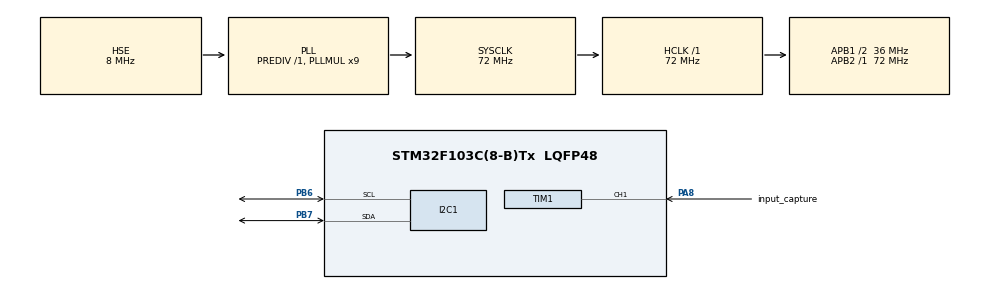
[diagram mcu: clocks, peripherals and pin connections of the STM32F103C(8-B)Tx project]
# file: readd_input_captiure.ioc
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Mcu.Family=STM32F1
Mcu.Name=STM32F103C(8-B)Tx
Mcu.Package=LQFP48
NVIC.PriorityGroup=NVIC_PRIORITYGROUP_4
NVIC.TIM1_CC_IRQn=true\:0\:0\:false\:false\:true\:true\:true\:true
PA13.Mode=Serial_Wire
PA13.Signal=SYS_JTMS-SWDIO
PA14.Mode=Serial_Wire
PA14.Signal=SYS_JTCK-SWCLK
PA8.GPIO_Label=input_capture
PA8.Signal=S_TIM1_CH1
PB6.Mode=I2C
PB6.Signal=I2C1_SCL
PB7.Mode=I2C
PB7.Signal=I2C1_SDA
PD0-OSC_IN.Mode=HSE-External-Oscillator
PD0-OSC_IN.Signal=RCC_OSC_IN
PD1-OSC_OUT.Mode=HSE-External-Oscillator
PD1-OSC_OUT.Signal=RCC_OSC_OUT
ProjectManager.HeapSize=0x200
ProjectManager.StackSize=0x400
ProjectManager.TargetToolchain=STM32CubeIDE
RCC.AHBFreq_Value=72000000
RCC.APB1CLKDivider=RCC_HCLK_DIV2
RCC.APB1Freq_Value=36000000
RCC.APB1TimFreq_Value=72000000
RCC.APB2Freq_Value=72000000
RCC.APB2TimFreq_Value=72000000
RCC.HCLKFreq_Value=72000000
RCC.PLLMUL=RCC_PLL_MUL9
RCC.PLLSourceVirtual=RCC_PLLSOURCE_HSE
RCC.SYSCLKFreq_VALUE=72000000
RCC.SYSCLKSource=RCC_SYSCLKSOURCE_PLLCLK
RCC.USBFreq_Value=72000000
SH.S_TIM1_CH1.0=TIM1_CH1,Input_Capture1_from_TI1
TIM1.Channel-Input_Capture1_from_TI1=TIM_CHANNEL_1
TIM1.Prescaler=71
board=custom

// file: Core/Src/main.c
#include "main.h"
#include<stdio.h>

I2C_HandleTypeDef hi2c1;

TIM_HandleTypeDef htim1;

void SystemClock_Config(void);
static void MX_GPIO_Init(void);
static void MX_I2C1_Init(void);
static void MX_TIM1_Init(void);

char lcd_buffer[16];
uint32_t IC_Value1 = 0, IC_Value2 = 0, Difference = 0;

uint8_t Is_First_Captured = 0;
float Distance = 0;

/* USER CODE BEGIN PFP */
void HAL_TIM_IC_CaptureCallback(TIM_HandleTypeDef *htim) {
    if (htim->Instance == TIM1 && htim->Channel == HAL_TIM_ACTIVE_CHANNEL_1) {
        if (Is_First_Captured == 0) { // Nếu đây là cạnh lên đầu tiên
            start = HAL_TIM_ReadCapturedValue(htim, TIM_CHANNEL_1);  // Lưu thời điểm bắt đầu xung
            Is_First_Captured = 1;  // Đánh dấu đã bắt đầu đo
            __HAL_TIM_SET_COUNTER(&htim1, 0);  // Reset bộ đếm Timer 1
        } else { // Nếu đây là cạnh xuống
            stop = HAL_TIM_ReadCapturedValue(htim, TIM_CHANNEL_1);  // Lưu thời điểm kết thúc xung

            // Xử lý tính toán khoảng cách
            if (stop > start) {
                Difference = stop - start;
            } else { // Nếu bộ đếm bị tràn (overflow)
                Difference = (0xFFFF - start) + stop;
            }

            distance = Difference * 0.0343 / 2;  // Tính khoảng cách (cm)
            Is_First_Captured = 0;  // Reset trạng thái đo
        }
    }
}

/* USER CODE END PFP */

int main(void)
{

  /* MCU Configuration--------------------------------------------------------*/

  /* Reset of all peripherals, Initializes the Flash interface and the Systick. */
  HAL_Init();

  /* Configure the system clock */
  SystemClock_Config();

  /* Initialize all configured peripherals */
  MX_GPIO_Init();
  MX_I2C1_Init();
  MX_TIM1_Init();
  /* USER CODE BEGIN 2 */
HAL_TIM_Base_Start_IT(&htim1);
  /* USER CODE END 2 */

  /* Infinite loop */
  while (1)
  {

  }
}

void SystemClock_Config(void)
{
  RCC_OscInitTypeDef RCC_OscInitStruct = {0};
  RCC_ClkInitTypeDef RCC_ClkInitStruct = {0};

  /** Initializes the RCC Oscillators according to the specified parameters
  * in the RCC_OscInitTypeDef structure.
  */
  RCC_OscInitStruct.OscillatorType = RCC_OSCILLATORTYPE_HSE;
  RCC_OscInitStruct.HSEState = RCC_HSE_ON;
  RCC_OscInitStruct.HSEPredivValue = RCC_HSE_PREDIV_DIV1;
  RCC_OscInitStruct.HSIState = RCC_HSI_ON;
  RCC_OscInitStruct.PLL.PLLState = RCC_PLL_ON;
  RCC_OscInitStruct.PLL.PLLSource = RCC_PLLSOURCE_HSE;
  RCC_OscInitStruct.PLL.PLLMUL = RCC_PLL_MUL9;
  if (HAL_RCC_OscConfig(&RCC_OscInitStruct) != HAL_OK)
  {
    Error_Handler();
  }

  /** Initializes the CPU, AHB and APB buses clocks
  */
  RCC_ClkInitStruct.ClockType = RCC_CLOCKTYPE_HCLK|RCC_CLOCKTYPE_SYSCLK
                              |RCC_CLOCKTYPE_PCLK1|RCC_CLOCKTYPE_PCLK2;
  RCC_ClkInitStruct.SYSCLKSource = RCC_SYSCLKSOURCE_PLLCLK;
  RCC_ClkInitStruct.AHBCLKDivider = RCC_SYSCLK_DIV1;
  RCC_ClkInitStruct.APB1CLKDivider = RCC_HCLK_DIV2;
  RCC_ClkInitStruct.APB2CLKDivider = RCC_HCLK_DIV1;

  if (HAL_RCC_ClockConfig(&RCC_ClkInitStruct, FLASH_LATENCY_2) != HAL_OK)
  {
    Error_Handler();
  }
}

static void MX_I2C1_Init(void)
{

  hi2c1.Instance = I2C1;
  hi2c1.Init.ClockSpeed = 100000;
  hi2c1.Init.DutyCycle = I2C_DUTYCYCLE_2;
  hi2c1.Init.OwnAddress1 = 0;
  hi2c1.Init.AddressingMode = I2C_ADDRESSINGMODE_7BIT;
  hi2c1.Init.DualAddressMode = I2C_DUALADDRESS_DISABLE;
  hi2c1.Init.OwnAddress2 = 0;
  hi2c1.Init.GeneralCallMode = I2C_GENERALCALL_DISABLE;
  hi2c1.Init.NoStretchMode = I2C_NOSTRETCH_DISABLE;
  if (HAL_I2C_Init(&hi2c1) != HAL_OK)
  {
    Error_Handler();
  }

}

static void MX_TIM1_Init(void)
{

  TIM_MasterConfigTypeDef sMasterConfig = {0};
  TIM_IC_InitTypeDef sConfigIC = {0};

  htim1.Instance = TIM1;
  htim1.Init.Prescaler = 71;
  htim1.Init.CounterMode = TIM_COUNTERMODE_UP;
  htim1.Init.Period = 65535;
  htim1.Init.ClockDivision = TIM_CLOCKDIVISION_DIV1;
  htim1.Init.RepetitionCounter = 0;
  htim1.Init.AutoReloadPreload = TIM_AUTORELOAD_PRELOAD_DISABLE;
  if (HAL_TIM_IC_Init(&htim1) != HAL_OK)
  {
    Error_Handler();
  }
  sMasterConfig.MasterOutputTrigger = TIM_TRGO_RESET;
  sMasterConfig.MasterSlaveMode = TIM_MASTERSLAVEMODE_DISABLE;
  if (HAL_TIMEx_MasterConfigSynchronization(&htim1, &sMasterConfig) != HAL_OK)
  {
    Error_Handler();
  }
  sConfigIC.ICPolarity = TIM_INPUTCHANNELPOLARITY_RISING;
  sConfigIC.ICSelection = TIM_ICSELECTION_DIRECTTI;
  sConfigIC.ICPrescaler = TIM_ICPSC_DIV1;
  sConfigIC.ICFilter = 0;
  if (HAL_TIM_IC_ConfigChannel(&htim1, &sConfigIC, TIM_CHANNEL_1) != HAL_OK)
  {
    Error_Handler();
  }

}

static void MX_GPIO_Init(void)
{

  /* GPIO Ports Clock Enable */
  __HAL_RCC_GPIOD_CLK_ENABLE();
  __HAL_RCC_GPIOA_CLK_ENABLE();
  __HAL_RCC_GPIOB_CLK_ENABLE();

}

void Error_Handler(void)
{
  __disable_irq();
  while (1)
  {
  }
}
